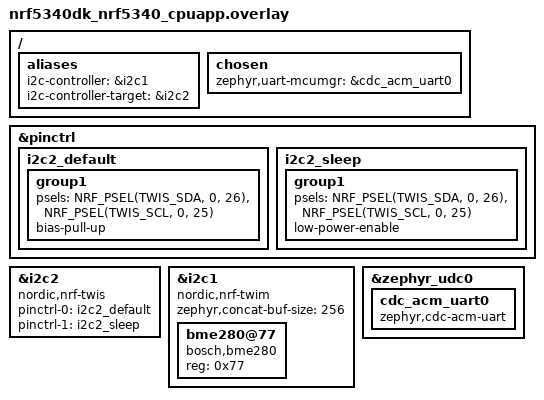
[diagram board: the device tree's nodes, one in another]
/ {
	aliases {
		i2c-controller = &i2c1;
		i2c-controller-target = &i2c2;
	};

	chosen {
		zephyr,uart-mcumgr = &cdc_acm_uart0;
	};
};

&pinctrl {
	i2c2_default: i2c2_default {
		group1 {
			psels = <NRF_PSEL(TWIS_SDA, 0, 26)>,
				<NRF_PSEL(TWIS_SCL, 0, 25)>;
			bias-pull-up;
		};
	};

	i2c2_sleep: i2c2_sleep {
		group1 {
			psels = <NRF_PSEL(TWIS_SDA, 0, 26)>,
				<NRF_PSEL(TWIS_SCL, 0, 25)>;
			low-power-enable;
		};
	};
};

&i2c2 {
	compatible = "nordic,nrf-twis";
	pinctrl-0 = <&i2c2_default>;
	pinctrl-1 = <&i2c2_sleep>;
	pinctrl-names = "default", "sleep";
	status = "okay";
};

&i2c1 {
	compatible = "nordic,nrf-twim";
	zephyr,concat-buf-size = <256>;
	status = "okay";
  bme280@77 {
    compatible = "bosch,bme280";
    reg = <0x77>;
  };
};

&zephyr_udc0 {
	cdc_acm_uart0: cdc_acm_uart0 {
		compatible = "zephyr,cdc-acm-uart";
	};
};
